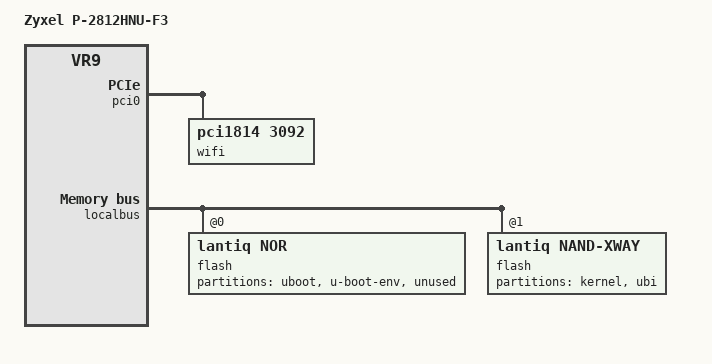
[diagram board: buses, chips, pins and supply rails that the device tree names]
#include "vr9_zyxel_p-2812hnu-fx.dtsi"

/ {
	compatible = "zyxel,p-2812hnu-f3", "zyxel,p-2812hnu", "lantiq,xway", "lantiq,vr9";
	model = "Zyxel P-2812HNU-F3";
};

&pci0 {
	wifi@e,0 {
		compatible = "pci1814,3092";
		reg = <0x7000 0 0 0 0>;

		ralink,eeprom-data = <0x92300201 0x000c4330 0x92009230 0x14180180 0x00009230 0x14180000 0x01006aff 0x1302ffff
				      0xffffc1ff 0xffffffff 0xffffffff 0xffffffff 0x8e750143 0x22082700 0xffff1601 0xffffd9fa
				      0xcc88ffff 0x0aff0000 0x00000000 0x0000ffff 0xffff0505 0x05050505 0x05050505 0x05050505
				      0x05050505 0x05050505 0x05050505 0x05051d1a 0x15110f0d 0x0a070401 0x00000000 0x00000000
				      0xffffffff 0xffffffff 0xffffffff 0xffffffff 0xffffffff 0xffffffff 0xffffffff 0xffffffff
				      0xffffffff 0xffffffff 0xffffffff 0xffffffff 0xffffffff 0xffffffff 0xffffffff 0xffffffff
				      0xffffffff 0xffffffff 0xffffffff 0xffffffff 0xffffffff 0xffffffff 0xffffffff 0xffff8888
				      0xccccaa88 0xccccaa88 0xccccaa88 0xccccaa88 0xffffffff 0xffffffff 0xffffffff 0xffffffff
				      0xffffffff 0xffffffff 0xffffffff 0xffffffff 0xffffffff 0xffffffff 0xffffffff 0xffffffff
				      0xffffffff 0xffffffff 0xffffffff 0xffffffff 0xffffffff 0xffffffff 0xffffffff 0xffffffff
				      0xffffffff 0xffffffff 0xffffffff 0xffffffff 0xffffffff 0xffffffff 0xffffffff 0xffffffff
				      0xffffffff 0xffffffff 0xffffffff 0xffffffff 0xffffffff 0xffffffff 0xffffffff 0xffffffff
				      0xffffffff 0xffffffff 0xffffffff 0xffffffff 0xffffffff 0xffffffff 0xffffffff 0xffffffff
				      0xffffffff 0xffffffff 0xffffffff 0xffffffff 0xffffffff 0xffffffff 0xffffffff 0xffffffff
				      0xffffffff 0xffffffff 0xffffffff 0xffffffff 0xffffffff 0xffffffff 0xffffffff 0xffffffff
				      0xffffffff 0xffffffff 0xffffffff 0xffffffff 0xffffffff 0xffffffff 0xffffffff 0xffffffff>;
	};
};

&localbus {
	flash@0 {
		compatible = "lantiq,nor";
		bank-width = <2>;
		reg = <0 0x0 0x800000>;

		pinctrl-0 = <&nand_pins>, <&nand_cs1_pins>;
		pinctrl-names = "default";

		partitions {
			compatible = "fixed-partitions";
			#address-cells = <1>;
			#size-cells = <1>;

			partition@0 {
				label = "uboot";
				reg = <0x0 0x50000>;
				read-only;
			};
			partition@50000 {
				label = "u-boot-env";
				reg = <0x50000 0x10000>;

				nvmem-layout {
					compatible = "u-boot,env";

					macaddr_uboot_ethaddr: ethaddr {
						#nvmem-cell-cells = <1>;
					};
				};
			};
			partition@60000 {
				label = "unused";
				reg = <0x60000 0x7a0000>;
			};
		};
	};

	flash@1 {
		compatible = "lantiq,nand-xway";
		lantiq,cs = <1>;
		bank-width = <2>;
		reg = <1 0x0 0x2000000>;
		#address-cells = <1>;
		#size-cells = <1>;

		nand-use-soft-ecc-engine;

		partition@0 {
			label = "kernel";
			reg = <0x0 0x200000>;
		};
		partition@200000 {
			label = "ubi";
			reg = <0x200000 0x7e00000>;
		};
	};
};
